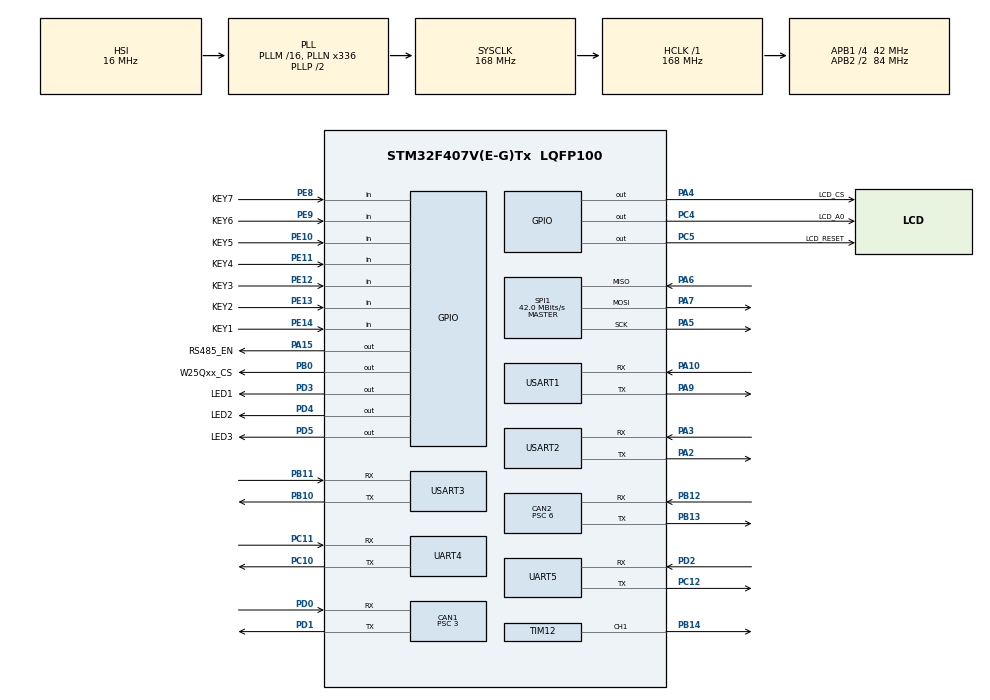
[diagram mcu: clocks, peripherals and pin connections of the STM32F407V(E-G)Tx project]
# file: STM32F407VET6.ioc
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CAN1.ABOM=ENABLE
CAN1.BS1=CAN_BS1_9TQ
CAN1.BS2=CAN_BS2_4TQ
CAN1.CalculateBaudRate=1000000
CAN1.CalculateTimeBit=1000
CAN1.CalculateTimeQuantum=71.42857142857143
CAN1.NART=ENABLE
CAN1.Prescaler=3
CAN1.SJW=CAN_SJW_3TQ
CAN2.ABOM=ENABLE
CAN2.BS1=CAN_BS1_9TQ
CAN2.BS2=CAN_BS2_4TQ
CAN2.CalculateBaudRate=500000
CAN2.CalculateTimeBit=2000
CAN2.CalculateTimeQuantum=142.85714285714286
CAN2.NART=ENABLE
CAN2.Prescaler=6
Dma.Request0=USART1_RX
Dma.Request1=USART1_TX
Dma.Request2=USART2_RX
Dma.Request3=USART2_TX
Dma.Request4=USART3_RX
Dma.Request5=USART3_TX
Dma.Request6=UART4_RX
Dma.Request7=UART4_TX
Dma.Request8=UART5_RX
Dma.Request9=UART5_TX
Dma.UART4_RX.6.Direction=DMA_PERIPH_TO_MEMORY
Dma.UART4_RX.6.FIFOMode=DMA_FIFOMODE_DISABLE
Dma.UART4_RX.6.Instance=DMA1_Stream2
Dma.UART4_RX.6.MemDataAlignment=DMA_MDATAALIGN_BYTE
Dma.UART4_RX.6.MemInc=DMA_MINC_ENABLE
Dma.UART4_RX.6.Mode=DMA_CIRCULAR
Dma.UART4_RX.6.PeriphDataAlignment=DMA_PDATAALIGN_BYTE
Dma.UART4_RX.6.PeriphInc=DMA_PINC_DISABLE
Dma.UART4_RX.6.Priority=DMA_PRIORITY_LOW
Dma.UART4_TX.7.Direction=DMA_MEMORY_TO_PERIPH
Dma.UART4_TX.7.FIFOMode=DMA_FIFOMODE_DISABLE
Dma.UART4_TX.7.Instance=DMA1_Stream4
Dma.UART4_TX.7.MemDataAlignment=DMA_MDATAALIGN_BYTE
Dma.UART4_TX.7.MemInc=DMA_MINC_ENABLE
Dma.UART4_TX.7.Mode=DMA_NORMAL
Dma.UART4_TX.7.PeriphDataAlignment=DMA_PDATAALIGN_BYTE
Dma.UART4_TX.7.PeriphInc=DMA_PINC_DISABLE
Dma.UART4_TX.7.Priority=DMA_PRIORITY_LOW
Dma.UART5_RX.8.Direction=DMA_PERIPH_TO_MEMORY
Dma.UART5_RX.8.FIFOMode=DMA_FIFOMODE_DISABLE
Dma.UART5_RX.8.Instance=DMA1_Stream0
Dma.UART5_RX.8.MemDataAlignment=DMA_MDATAALIGN_BYTE
Dma.UART5_RX.8.MemInc=DMA_MINC_ENABLE
Dma.UART5_RX.8.Mode=DMA_CIRCULAR
Dma.UART5_RX.8.PeriphDataAlignment=DMA_PDATAALIGN_BYTE
Dma.UART5_RX.8.PeriphInc=DMA_PINC_DISABLE
Dma.UART5_RX.8.Priority=DMA_PRIORITY_LOW
Dma.UART5_TX.9.Direction=DMA_MEMORY_TO_PERIPH
Dma.UART5_TX.9.FIFOMode=DMA_FIFOMODE_DISABLE
Dma.UART5_TX.9.Instance=DMA1_Stream7
Dma.UART5_TX.9.MemDataAlignment=DMA_MDATAALIGN_BYTE
Dma.UART5_TX.9.MemInc=DMA_MINC_ENABLE
Dma.UART5_TX.9.Mode=DMA_NORMAL
Dma.UART5_TX.9.PeriphDataAlignment=DMA_PDATAALIGN_BYTE
Dma.UART5_TX.9.PeriphInc=DMA_PINC_DISABLE
Dma.UART5_TX.9.Priority=DMA_PRIORITY_LOW
Dma.USART1_RX.0.Direction=DMA_PERIPH_TO_MEMORY
Dma.USART1_RX.0.FIFOMode=DMA_FIFOMODE_DISABLE
Dma.USART1_RX.0.Instance=DMA2_Stream2
Dma.USART1_RX.0.MemDataAlignment=DMA_MDATAALIGN_BYTE
Dma.USART1_RX.0.MemInc=DMA_MINC_ENABLE
Dma.USART1_RX.0.Mode=DMA_CIRCULAR
Dma.USART1_RX.0.PeriphDataAlignment=DMA_PDATAALIGN_BYTE
Dma.USART1_RX.0.PeriphInc=DMA_PINC_DISABLE
Dma.USART1_RX.0.Priority=DMA_PRIORITY_LOW
Dma.USART1_TX.1.Direction=DMA_MEMORY_TO_PERIPH
Dma.USART1_TX.1.FIFOMode=DMA_FIFOMODE_DISABLE
Dma.USART1_TX.1.Instance=DMA2_Stream7
Dma.USART1_TX.1.MemDataAlignment=DMA_MDATAALIGN_BYTE
Dma.USART1_TX.1.MemInc=DMA_MINC_ENABLE
Dma.USART1_TX.1.Mode=DMA_NORMAL
Dma.USART1_TX.1.PeriphDataAlignment=DMA_PDATAALIGN_BYTE
Dma.USART1_TX.1.PeriphInc=DMA_PINC_DISABLE
Dma.USART1_TX.1.Priority=DMA_PRIORITY_LOW
Dma.USART2_RX.2.Direction=DMA_PERIPH_TO_MEMORY
Dma.USART2_RX.2.FIFOMode=DMA_FIFOMODE_DISABLE
Dma.USART2_RX.2.Instance=DMA1_Stream5
Dma.USART2_RX.2.MemDataAlignment=DMA_MDATAALIGN_BYTE
Dma.USART2_RX.2.MemInc=DMA_MINC_ENABLE
Dma.USART2_RX.2.Mode=DMA_CIRCULAR
Dma.USART2_RX.2.PeriphDataAlignment=DMA_PDATAALIGN_BYTE
Dma.USART2_RX.2.PeriphInc=DMA_PINC_DISABLE
Dma.USART2_RX.2.Priority=DMA_PRIORITY_LOW
Dma.USART2_TX.3.Direction=DMA_MEMORY_TO_PERIPH
Dma.USART2_TX.3.FIFOMode=DMA_FIFOMODE_DISABLE
Dma.USART2_TX.3.Instance=DMA1_Stream6
Dma.USART2_TX.3.MemDataAlignment=DMA_MDATAALIGN_BYTE
Dma.USART2_TX.3.MemInc=DMA_MINC_ENABLE
Dma.USART2_TX.3.Mode=DMA_NORMAL
Dma.USART2_TX.3.PeriphDataAlignment=DMA_PDATAALIGN_BYTE
Dma.USART2_TX.3.PeriphInc=DMA_PINC_DISABLE
Dma.USART2_TX.3.Priority=DMA_PRIORITY_LOW
Dma.USART3_RX.4.Direction=DMA_PERIPH_TO_MEMORY
Dma.USART3_RX.4.FIFOMode=DMA_FIFOMODE_DISABLE
Dma.USART3_RX.4.Instance=DMA1_Stream1
Dma.USART3_RX.4.MemDataAlignment=DMA_MDATAALIGN_BYTE
Dma.USART3_RX.4.MemInc=DMA_MINC_ENABLE
Dma.USART3_RX.4.Mode=DMA_CIRCULAR
Dma.USART3_RX.4.PeriphDataAlignment=DMA_PDATAALIGN_BYTE
Dma.USART3_RX.4.PeriphInc=DMA_PINC_DISABLE
Dma.USART3_RX.4.Priority=DMA_PRIORITY_LOW
Dma.USART3_TX.5.Direction=DMA_MEMORY_TO_PERIPH
Dma.USART3_TX.5.FIFOMode=DMA_FIFOMODE_DISABLE
Dma.USART3_TX.5.Instance=DMA1_Stream3
Dma.USART3_TX.5.MemDataAlignment=DMA_MDATAALIGN_BYTE
Dma.USART3_TX.5.MemInc=DMA_MINC_ENABLE
Dma.USART3_TX.5.Mode=DMA_NORMAL
Dma.USART3_TX.5.PeriphDataAlignment=DMA_PDATAALIGN_BYTE
Dma.USART3_TX.5.PeriphInc=DMA_PINC_DISABLE
Dma.USART3_TX.5.Priority=DMA_PRIORITY_LOW
Mcu.Family=STM32F4
Mcu.Name=STM32F407V(E-G)Tx
Mcu.Package=LQFP100
NVIC.CAN1_RX0_IRQn=true\:0\:0\:false\:false\:true\:false\:true\:true
NVIC.CAN2_RX0_IRQn=true\:0\:0\:false\:false\:true\:false\:true\:true
NVIC.DMA1_Stream0_IRQn=true\:0\:0\:false\:false\:true\:false\:false\:true
NVIC.DMA1_Stream1_IRQn=true\:0\:0\:false\:false\:true\:false\:false\:true
NVIC.DMA1_Stream2_IRQn=true\:0\:0\:false\:false\:true\:false\:false\:true
NVIC.DMA1_Stream3_IRQn=true\:0\:0\:false\:false\:true\:false\:false\:true
NVIC.DMA1_Stream4_IRQn=true\:0\:0\:false\:false\:true\:false\:false\:true
NVIC.DMA1_Stream5_IRQn=true\:0\:0\:false\:false\:true\:false\:false\:true
NVIC.DMA1_Stream6_IRQn=true\:0\:0\:false\:false\:true\:false\:false\:true
NVIC.DMA1_Stream7_IRQn=true\:0\:0\:false\:false\:true\:false\:false\:true
NVIC.DMA2_Stream2_IRQn=true\:0\:0\:false\:false\:true\:false\:false\:true
NVIC.DMA2_Stream7_IRQn=true\:0\:0\:false\:false\:true\:false\:false\:true
NVIC.PriorityGroup=NVIC_PRIORITYGROUP_4
NVIC.UART4_IRQn=true\:0\:0\:false\:false\:true\:false\:true\:true
NVIC.UART5_IRQn=true\:0\:0\:false\:false\:true\:false\:true\:true
NVIC.USART1_IRQn=true\:0\:0\:false\:false\:true\:false\:true\:true
NVIC.USART2_IRQn=true\:0\:0\:false\:false\:true\:false\:true\:true
NVIC.USART3_IRQn=true\:0\:0\:false\:false\:true\:false\:true\:true
PA10.Mode=Asynchronous
PA10.Signal=USART1_RX
PA13.Mode=Serial_Wire
PA13.Signal=SYS_JTMS-SWDIO
PA14.Mode=Serial_Wire
PA14.Signal=SYS_JTCK-SWCLK
PA15.GPIO_Label=RS485_EN
PA15.Signal=GPIO_Output
PA2.Mode=Asynchronous
PA2.Signal=USART2_TX
PA3.Mode=Asynchronous
PA3.Signal=USART2_RX
PA4.GPIO_Label=LCD_CS
PA4.Signal=GPIO_Output
PA5.Mode=Full_Duplex_Master
PA5.Signal=SPI1_SCK
PA6.Mode=Full_Duplex_Master
PA6.Signal=SPI1_MISO
PA7.Mode=Full_Duplex_Master
PA7.Signal=SPI1_MOSI
PA9.Mode=Asynchronous
PA9.Signal=USART1_TX
PB0.GPIO_Label=W25Qxx_CS
PB0.Signal=GPIO_Output
PB10.Mode=Asynchronous
PB10.Signal=USART3_TX
PB11.Mode=Asynchronous
PB11.Signal=USART3_RX
PB12.Mode=CAN_Activate
PB12.Signal=CAN2_RX
PB13.Mode=CAN_Activate
PB13.Signal=CAN2_TX
PB14.Signal=S_TIM12_CH1
PC10.Mode=Asynchronous
PC10.Signal=UART4_TX
PC11.Mode=Asynchronous
PC11.Signal=UART4_RX
PC12.Mode=Asynchronous
PC12.Signal=UART5_TX
PC4.GPIO_Label=LCD_A0
PC4.Signal=GPIO_Output
PC5.GPIO_Label=LCD_RESET
PC5.Signal=GPIO_Output
PD0.Mode=CAN_Activate
PD0.Signal=CAN1_RX
PD1.Mode=CAN_Activate
PD1.Signal=CAN1_TX
PD2.Mode=Asynchronous
PD2.Signal=UART5_RX
PD3.GPIO_Label=LED1
PD3.GPIO_ModeDefaultOutputPP=GPIO_MODE_OUTPUT_OD
PD3.GPIO_PuPd=GPIO_NOPULL
PD3.PinState=GPIO_PIN_SET
PD3.Signal=GPIO_Output
PD4.GPIO_Label=LED2
PD4.GPIO_ModeDefaultOutputPP=GPIO_MODE_OUTPUT_OD
PD4.GPIO_PuPd=GPIO_NOPULL
PD4.PinState=GPIO_PIN_SET
PD4.Signal=GPIO_Output
PD5.GPIO_Label=LED3
PD5.GPIO_ModeDefaultOutputPP=GPIO_MODE_OUTPUT_OD
PD5.GPIO_PuPd=GPIO_NOPULL
PD5.PinState=GPIO_PIN_SET
PD5.Signal=GPIO_Output
PE10.GPIO_Label=KEY5
PE10.GPIO_PuPd=GPIO_PULLUP
PE10.Signal=GPIO_Input
PE11.GPIO_Label=KEY4
PE11.GPIO_PuPd=GPIO_PULLUP
PE11.Signal=GPIO_Input
PE12.GPIO_Label=KEY3
PE12.GPIO_PuPd=GPIO_PULLUP
PE12.Signal=GPIO_Input
PE13.GPIO_Label=KEY2
PE13.GPIO_PuPd=GPIO_PULLUP
PE13.Signal=GPIO_Input
PE14.GPIO_Label=KEY1
PE14.GPIO_PuPd=GPIO_PULLUP
PE14.Signal=GPIO_Input
PE8.GPIO_Label=KEY7
PE8.GPIO_PuPd=GPIO_PULLUP
PE8.Signal=GPIO_Input
PE9.GPIO_Label=KEY6
PE9.GPIO_PuPd=GPIO_PULLUP
PE9.Signal=GPIO_Input
PH0-OSC_IN.Mode=HSE-External-Oscillator
PH0-OSC_IN.Signal=RCC_OSC_IN
PH1-OSC_OUT.Mode=HSE-External-Oscillator
PH1-OSC_OUT.Signal=RCC_OSC_OUT
ProjectManager.HeapSize=0x200
ProjectManager.StackSize=0x400
ProjectManager.TargetToolchain=MDK-ARM V5.32
RCC.48MHZClocksFreq_Value=84000000
RCC.AHBFreq_Value=168000000
RCC.APB1CLKDivider=RCC_HCLK_DIV4
RCC.APB1Freq_Value=42000000
RCC.APB1TimFreq_Value=84000000
RCC.APB2CLKDivider=RCC_HCLK_DIV2
RCC.APB2Freq_Value=84000000
RCC.APB2TimFreq_Value=168000000
RCC.CortexFreq_Value=168000000
RCC.HCLKFreq_Value=168000000
RCC.HSE_VALUE=8000000
RCC.HSI_VALUE=16000000
RCC.LSE_VALUE=32768
RCC.PLLN=336
RCC.SYSCLKFreq_VALUE=168000000
RCC.SYSCLKSource=RCC_SYSCLKSOURCE_PLLCLK
RCC.VCOOutputFreq_Value=336000000
RealThread.RT-Thread.3.1.5.RTOSJjkernel=true
RealThread.RT-Thread.3.1.5.RTOSJjshell=true
RealThread.RT-Thread.3.1.5.RT_MAIN_THREAD_STACK_SIZE=512
RealThread.RT-Thread.3.1.5.RT_USING_HEAP=1
RealThread.RT-Thread.3.1.5.RT_USING_MESSAGEQUEUE=1
RealThread.RT-Thread.3.1.5.RT_USING_MUTEX=1
SH.S_TIM12_CH1.0=TIM12_CH1,PWM Generation1 CH1
SPI1.CalculateBaudRate=42.0 MBits/s
SPI1.Direction=SPI_DIRECTION_2LINES
SPI1.Mode=SPI_MODE_MASTER
SPI1.VirtualType=VM_MASTER
TIM12.Channel-PWM\ Generation1\ CH1=TIM_CHANNEL_1
TIM12.Period=1999
TIM12.Prescaler=5
UART4.VirtualMode=Asynchronous
UART5.VirtualMode=Asynchronous
USART1.VirtualMode=VM_ASYNC
USART2.VirtualMode=VM_ASYNC
USART3.VirtualMode=VM_ASYNC
VP_RealThread.RT-Thread_VS_RTOSJjkernel_3.1.5_3.1.5.Mode=RTOSJjkernel
VP_RealThread.RT-Thread_VS_RTOSJjshell_3.1.5_3.1.5.Mode=RTOSJjshell
board=custom

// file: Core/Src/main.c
/* USER CODE BEGIN Header */
/**
  ******************************************************************************
  * @file           : main.c
  * @brief          : Main program body
  ******************************************************************************
  * @attention
  *
  * Copyright (c) 2022 STMicroelectronics.
  * All rights reserved.
  *
  * This software is licensed under terms that can be found in the LICENSE file
  * in the root directory of this software component.
  * If no LICENSE file comes with this software, it is provided AS-IS.
  *
  ******************************************************************************
  */
#include "bsp.h"
#if SYS_SUPPORT_OS
#include "main.h"
#include <rtthread.h>
#else
/* USER CODE END Header */
#include "main.h"
#include "can.h"
#include "dma.h"
#include "spi.h"
#include "tim.h"
#include "usart.h"
#include "gpio.h"

/* USER CODE BEGIN Includes */
#endif
/* USER CODE END Includes */

void SystemClock_Config(void);

int main(void)
{
  /* USER CODE BEGIN 1 */
#if SYS_SUPPORT_OS == 0
  /* USER CODE END 1 */

  /* MCU Configuration--------------------------------------------------------*/

  /* Reset of all peripherals, Initializes the Flash interface and the Systick. */
  HAL_Init();

  /* Configure the system clock */
  SystemClock_Config();

  /* Initialize all configured peripherals */
  MX_GPIO_Init();
  MX_DMA_Init();
  MX_SPI1_Init();
  MX_TIM12_Init();
  MX_USART1_UART_Init();
  MX_USART2_UART_Init();
  MX_USART3_UART_Init();
  MX_UART4_Init();
  MX_UART5_Init();
  MX_CAN1_Init();
  MX_CAN2_Init();

  /* Infinite loop */
  /* USER CODE BEGIN WHILE */
  while (1)
  {
	  HAL_GPIO_TogglePin(GPIOD, LED1_Pin|LED2_Pin|LED3_Pin);
	  HAL_Delay(500);
    /* USER CODE END WHILE */

    /* USER CODE BEGIN 3 */
  }
#else
  return 0;
#endif
  /* USER CODE END 3 */
}

void SystemClock_Config(void)
{
  RCC_OscInitTypeDef RCC_OscInitStruct = {0};
  RCC_ClkInitTypeDef RCC_ClkInitStruct = {0};

  /** Configure the main internal regulator output voltage
  */
  __HAL_RCC_PWR_CLK_ENABLE();
  __HAL_PWR_VOLTAGESCALING_CONFIG(PWR_REGULATOR_VOLTAGE_SCALE1);
  /** Initializes the RCC Oscillators according to the specified parameters
  * in the RCC_OscInitTypeDef structure.
  */
  RCC_OscInitStruct.OscillatorType = RCC_OSCILLATORTYPE_HSI;
  RCC_OscInitStruct.HSIState = RCC_HSI_ON;
  RCC_OscInitStruct.HSICalibrationValue = RCC_HSICALIBRATION_DEFAULT;
  RCC_OscInitStruct.PLL.PLLState = RCC_PLL_ON;
  RCC_OscInitStruct.PLL.PLLSource = RCC_PLLSOURCE_HSI;
  RCC_OscInitStruct.PLL.PLLM = 16;
  RCC_OscInitStruct.PLL.PLLN = 336;
  RCC_OscInitStruct.PLL.PLLP = RCC_PLLP_DIV2;
  RCC_OscInitStruct.PLL.PLLQ = 4;
  if (HAL_RCC_OscConfig(&RCC_OscInitStruct) != HAL_OK)
  {
    Error_Handler();
  }
  /** Initializes the CPU, AHB and APB buses clocks
  */
  RCC_ClkInitStruct.ClockType = RCC_CLOCKTYPE_HCLK|RCC_CLOCKTYPE_SYSCLK
                              |RCC_CLOCKTYPE_PCLK1|RCC_CLOCKTYPE_PCLK2;
  RCC_ClkInitStruct.SYSCLKSource = RCC_SYSCLKSOURCE_PLLCLK;
  RCC_ClkInitStruct.AHBCLKDivider = RCC_SYSCLK_DIV1;
  RCC_ClkInitStruct.APB1CLKDivider = RCC_HCLK_DIV4;
  RCC_ClkInitStruct.APB2CLKDivider = RCC_HCLK_DIV2;

  if (HAL_RCC_ClockConfig(&RCC_ClkInitStruct, FLASH_LATENCY_5) != HAL_OK)
  {
    Error_Handler();
  }
}

void Error_Handler(void)
{
  __disable_irq();
  while (1)
  {
  }
}
